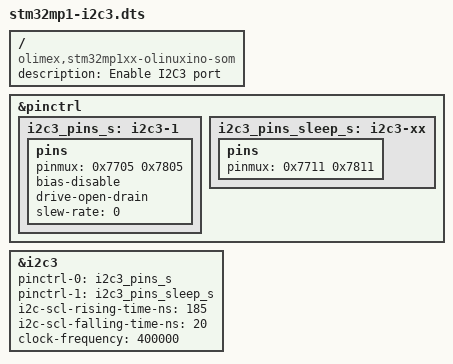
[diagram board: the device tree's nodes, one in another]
/dts-v1/;
/plugin/;

/ {
	compatible = "olimex,stm32mp1xx-olinuxino-som";
	description = "Enable I2C3 port";

	fragment@0 {
		target = <&pinctrl>;
		__overlay__ {
			i2c3_pins_s: i2c3-1 {
				pins {
					pinmux = <0x7705 0x7805>;
					bias-disable;				 /*pull disable*/
					drive-open-drain;			 /*open drain enable*/
					slew-rate = <0>;
				};
			};

			i2c3_pins_sleep_s: i2c3-xx {
				pins {
					pinmux = <0x7711 0x7811>;
				};
			};
		};
	};

	fragment@1 {
		target = <&i2c3>;
		__overlay__ {
			pinctrl-names = "default", "sleep";
			pinctrl-0 = <&i2c3_pins_s>;
			pinctrl-1 = <&i2c3_pins_sleep_s>;
			i2c-scl-rising-time-ns = <185>;
			i2c-scl-falling-time-ns = <20>;
			clock-frequency = <400000>;
			status = "okay";
			/delete-property/dmas;
			/delete-property/dma-names;
		};
	};
};
